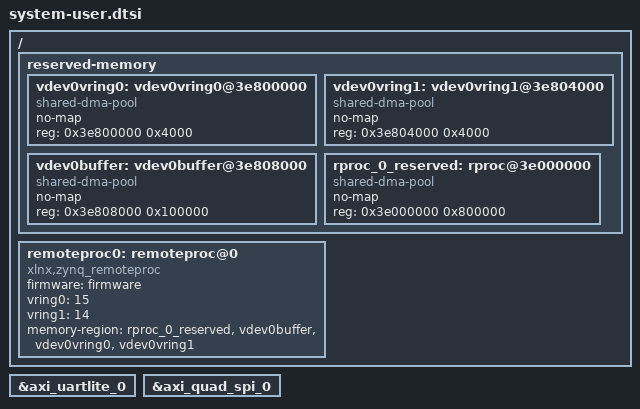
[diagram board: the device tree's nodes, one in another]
/include/ "system-conf.dtsi"
/ {
	reserved-memory {
		#address-cells = <1>;
		#size-cells = <1>;
		ranges;
		vdev0vring0: vdev0vring0@3e800000 {
			no-map;
			compatible = "shared-dma-pool";
			reg = <0x3e800000 0x4000>;
		};
		vdev0vring1: vdev0vring1@3e804000 {
			no-map;
			compatible = "shared-dma-pool";
			reg = <0x3e804000 0x4000>;
		};
		vdev0buffer: vdev0buffer@3e808000 {
			no-map;
			compatible = "shared-dma-pool";
			reg = <0x3e808000 0x100000>;
		};
		rproc_0_reserved: rproc@3e000000 {
			no-map;
			compatible = "shared-dma-pool";
			reg = <0x3e000000 0x800000>;
		};
	};
	
	remoteproc0: remoteproc@0 {
		compatible = "xlnx,zynq_remoteproc";
		firmware = "firmware";
		vring0 = <15>;
		vring1 = <14>;
		memory-region = <&rproc_0_reserved>, <&vdev0buffer>, <&vdev0vring0>, 
		<&vdev0vring1>;
	};


};

&axi_uartlite_0 {
	status = "okay";
};

&axi_quad_spi_0 {
	status = "okay";
};


//&uart0 {
//	status = "true";
//};

//&i2c0 {
//	clock-frequency = <400000>;
//	status = "disabled";
//};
